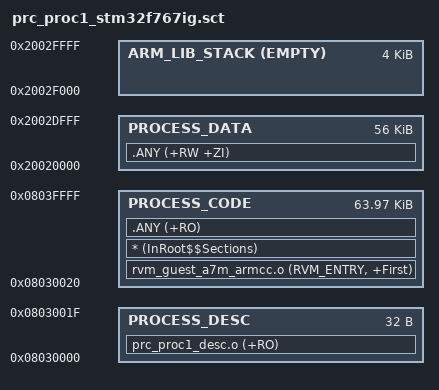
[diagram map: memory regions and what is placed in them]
;******************************************************************************
;Filename    : proc_proc1_stm32f767ig.sct
;Author      : The RVM project generator.
;Date        : 15/07/2024 19:11:05
;Licence     : Unlicense; see COPYING for details.
;Description : The scatter file for ARMv7-M layout. This file is intended
;              to be used with STM32F767IG.
;******************************************************************************

;Descriptor *******************************************************************
DESC 0x8030000 0x20
{
    ;Process header segment
    PROCESS_DESC 0x8030000 0x20
    {
        ;Process header
        prc_proc1_desc.o         (+RO)
    }
}
;End Descriptor ***************************************************************

;Process **********************************************************************
PROCESS 0x8030020 0xFFE0
{
    ;Process code segment
    PROCESS_CODE 0x8030020 0xFFE0
    {
        ;Entry point assembly
        rvm_guest_a7m_armcc.o     (RVM_ENTRY, +First)
        ;The lib code copying code
        *                      (InRoot$$Sections)
        ;The other code sections
        .ANY                   (+RO)
    }

    ;Process data segment
    PROCESS_DATA 0x20020000 0xE000
    {
        .ANY                   (+RW +ZI)
    }

    ;Process stack segment - required by armlib; reusing the booting thread's
    ARM_LIB_STACK 0x2002F000 EMPTY 0x1000
    {

    }
}
;End Process ******************************************************************

;End Of File ******************************************************************

;Copyright (C) Evo-Devo Instrum. All rights reserved **************************

